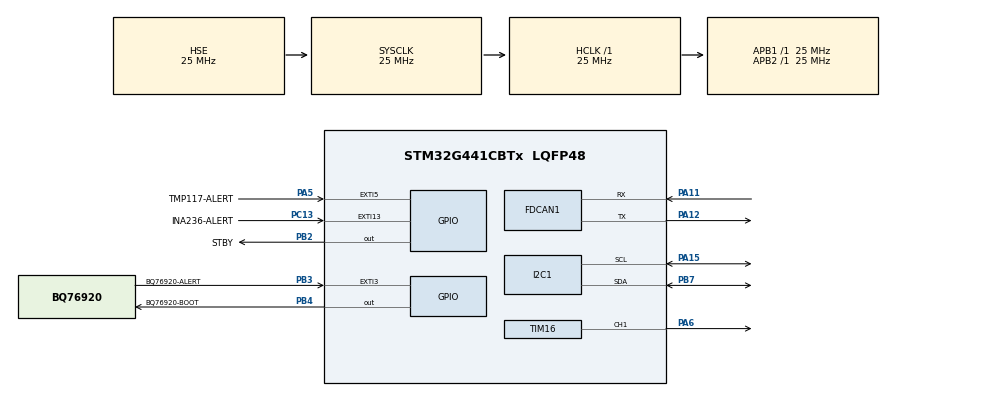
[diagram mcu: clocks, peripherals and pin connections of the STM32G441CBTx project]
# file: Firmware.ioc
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FDCAN1.CalculateBaudRateNominal=520833
FDCAN1.CalculateTimeBitNominal=1920
FDCAN1.CalculateTimeQuantumNominal=640.0
FREERTOS.Tasks01=defaultTask,24,128,StartDefaultTask,Default,NULL,Dynamic,NULL,NULL
I2C1.Timing=0x0080608D
Mcu.Family=STM32G4
Mcu.Name=STM32G441CBTx
Mcu.Package=LQFP48
NVIC.EXTI15_10_IRQn=true\:5\:0\:false\:true\:true\:5\:true\:true\:true\:true
NVIC.EXTI3_IRQn=true\:5\:0\:false\:true\:true\:2\:true\:true\:true\:true
NVIC.EXTI9_5_IRQn=true\:5\:0\:false\:true\:true\:4\:true\:true\:true\:true
NVIC.FDCAN1_IT0_IRQn=true\:5\:0\:false\:true\:true\:3\:true\:true\:true\:true
NVIC.PriorityGroup=NVIC_PRIORITYGROUP_4
NVIC.RCC_IRQn=true\:5\:0\:false\:true\:true\:1\:true\:true\:false\:true
NVIC.TimeBase=TIM6_DAC_IRQn
NVIC.TimeBaseIP=TIM6
PA11.Mode=FDCAN_Activate
PA11.Signal=FDCAN1_RX
PA12.Mode=FDCAN_Activate
PA12.Signal=FDCAN1_TX
PA13.Mode=Serial_Wire
PA13.Signal=SYS_JTMS-SWDIO
PA14.Mode=Serial_Wire
PA14.Signal=SYS_JTCK-SWCLK
PA15.Mode=I2C
PA15.Signal=I2C1_SCL
PA5.GPIO_Label=TMP117-ALERT
PA5.Signal=GPXTI5
PA6.Signal=S_TIM16_CH1
PB2.GPIO_Label=STBY
PB2.Signal=GPIO_Output
PB3.GPIO_Label=BQ76920-ALERT
PB3.Signal=GPXTI3
PB4.GPIO_Label=BQ76920-BOOT
PB4.Signal=GPIO_Output
PB7.Mode=I2C
PB7.Signal=I2C1_SDA
PC13.GPIO_Label=INA236-ALERT
PC13.Signal=GPXTI13
PF0-OSC_IN.Mode=HSE-External-Oscillator
PF0-OSC_IN.Signal=RCC_OSC_IN
PF1-OSC_OUT.Mode=HSE-External-Oscillator
PF1-OSC_OUT.Signal=RCC_OSC_OUT
ProjectManager.HeapSize=0x200
ProjectManager.StackSize=0x400
ProjectManager.TargetToolchain=CMake
RCC.ADC12Freq_Value=25000000
RCC.AHBFreq_Value=25000000
RCC.APB1Freq_Value=25000000
RCC.APB1TimFreq_Value=25000000
RCC.APB2Freq_Value=25000000
RCC.APB2TimFreq_Value=25000000
RCC.CortexFreq_Value=25000000
RCC.EXTERNAL_CLOCK_VALUE=12288000
RCC.HCLKFreq_Value=25000000
RCC.HSE_VALUE=25000000
RCC.HSI48_VALUE=48000000
RCC.HSI_VALUE=16000000
RCC.I2C1CLockSelection=RCC_I2C1CLKSOURCE_SYSCLK
RCC.LSE_VALUE=32768
RCC.PLLSourceVirtual=RCC_PLLSOURCE_HSE
RCC.SYSCLKFreq_VALUE=25000000
RCC.SYSCLKSource=RCC_SYSCLKSOURCE_HSE
RCC.USBFreq_Value=100000000
RCC.VCOOutputFreq_Value=200000000
SH.S_TIM16_CH1.0=TIM16_CH1,PWM Generation1 CH1
TIM16.Channel=TIM_CHANNEL_1
VP_FREERTOS_VS_CMSIS_V2.Mode=CMSIS_V2
VP_SYS_VS_DBSignals.Mode=DisableDeadBatterySignals
VP_SYS_VS_tim6.Mode=TIM6
VP_TIM16_VS_ClockSourceINT.Mode=Enable_Timer
board=custom

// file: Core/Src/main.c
/* USER CODE BEGIN Header */
/**
 ******************************************************************************
 * @file           : main.c
 * @brief          : Main program body
 ******************************************************************************
 * @attention
 *
 * Copyright (c) 2026 STMicroelectronics.
 * All rights reserved.
 *
 * This software is licensed under terms that can be found in the LICENSE file
 * in the root directory of this software component.
 * If no LICENSE file comes with this software, it is provided AS-IS.
 *
 ******************************************************************************
 */
/* USER CODE END Header */
#include "main.h"
#include "INA236.h"
#include "bq76920.h"
#include "tmp117.h"
#include "cmsis_os.h"
#include "cmsis_os2.h"
#include "fdcan.h"
#include "gpio.h"
#include "i2c.h"
#include "ina236.h"
#include "stm32g4xx_hal.h"
#include "tim.h"
#include "tmp117.h"

BQ76920 bq;
INA236 ina;
TMP117 tmp;

void SystemClock_Config(void);
void MX_FREERTOS_Init(void);
static void MX_NVIC_Init(void);

/* USER CODE BEGIN 0 */
void BQ76920Task(void *argument);
void INA236Task(void *argument);
void TMP117Task(void *argument);
/* USER CODE END 0 */

// RTOS Tasks
osThreadId_t BQ76920TaskHandle;
const osThreadAttr_t BQ76920Task_attr = {
    .name = "BQ76920 Task",
    .stack_size = 256 * 4,
    .priority = (osPriority_t)osPriorityNormal,
};

osThreadId_t INA236TaskHandle;
const osThreadAttr_t INA236Task_attr = {
    .name = "INA236 Task",
    .stack_size = 256 * 4,
    .priority = (osPriority_t)osPriorityNormal,
};

osThreadId_t TMP117TaskHandle;
const osThreadAttr_t TMP117Task_attr = {
    .name = "TMP117 Task",
    .stack_size = 256 * 4,
    .priority = (osPriority_t)osPriorityNormal,
};

// Mutexes
osMutexId_t i2cMutex;
const osMutexAttr_t i2cMutex_attr = {.name = "i2cMutex"};
int main(void) {
  SCB->VTOR = 0x08000000;
  __DSB();
  __ISB();

  /* MCU Configuration--------------------------------------------------------*/

  /* Reset of all peripherals, Initializes the Flash interface and the Systick.
   */
  HAL_Init();

  /* Configure the system clock */
  SystemClock_Config();
  /* USER CODE BEGIN SysInit */
  MX_NVIC_Init();
  /* USER CODE END SysInit */
  NVIC_ClearPendingIRQ(TIM6_DAC_IRQn);
  NVIC_SetPendingIRQ(TIM6_DAC_IRQn);

  extern TIM_HandleTypeDef htim6;

  __enable_irq();

  HAL_NVIC_SetPriority(TIM6_DAC_IRQn, 15, 0);
  HAL_NVIC_EnableIRQ(TIM6_DAC_IRQn);

  __HAL_TIM_CLEAR_FLAG(&htim6, TIM_FLAG_UPDATE);
  __HAL_TIM_ENABLE_IT(&htim6, TIM_IT_UPDATE);
  HAL_TIM_Base_Start_IT(&htim6);
  /* Initialize all configured peripherals */
  MX_GPIO_Init();
  MX_FDCAN1_Init();
  MX_I2C1_Init();
  MX_TIM16_Init();

  /* Initialize interrupts */
  MX_NVIC_Init();
  /* USER CODE BEGIN 2 */
  BQ76920_Initialize(&bq, &hi2c1, BQ76920_ALERT_GPIO_Port, BQ76920_ALERT_Pin,
                     BQ76920_BOOT_GPIO_Port, BQ76920_BOOT_Pin);
  readCells(&bq);

  INA236_Initialize(&ina, &hi2c1);
  getINA236(&ina);

  TMP117_Initialize(&tmp, &hi2c1);
  readTMP117(&tmp);
  /* USER CODE END 2 */

  /* Init scheduler */
  osKernelInitialize(); /* Call init function for freertos objects (in
                           cmsis_os2.c) */

  i2cMutex = osMutexNew(&i2cMutex_attr);
  if (i2cMutex == NULL) {
    Error_Handler();
  }
  INA236TaskHandle = osThreadNew(INA236Task, NULL, &INA236Task_attr);
  BQ76920TaskHandle = osThreadNew(BQ76920Task, NULL, &BQ76920Task_attr);
  TMP117TaskHandle = osThreadNew(TMP117Task, NULL, &TMP117Task_attr);
  /* Start scheduler */
  osKernelStart();

  /* We should never get here as control is now taken by the scheduler */

  /* Infinite loop */
  while (1) {

  }
}
void BQ76920Task(void *argument) {
  for (;;) {
    osMutexAcquire(i2cMutex, osWaitForever);
    readCells(&bq);
    osMutexRelease(i2cMutex);
    osDelay(5);
  }
}

void INA236Task(void *argument) {
  for (;;) {
    osMutexAcquire(i2cMutex, osWaitForever);
    getINA236(&ina);
    osMutexRelease(i2cMutex);
    osDelay(5);
  }
}
void TMP117Task(void *argument)
{
  for (;;) {
    osMutexAcquire(i2cMutex, osWaitForever);
    readTMP117(&tmp);
    osMutexRelease(i2cMutex);
    osDelay(5);
  }
}
void SystemClock_Config(void)
{
  RCC_OscInitTypeDef RCC_OscInitStruct = {0};
  RCC_ClkInitTypeDef RCC_ClkInitStruct = {0};

  /** Configure the main internal regulator output voltage
  */
  HAL_PWREx_ControlVoltageScaling(PWR_REGULATOR_VOLTAGE_SCALE1);

  /** Initializes the RCC Oscillators according to the specified parameters
  * in the RCC_OscInitTypeDef structure.
  */
  RCC_OscInitStruct.OscillatorType = RCC_OSCILLATORTYPE_HSE;
  RCC_OscInitStruct.HSEState = RCC_HSE_ON;
  RCC_OscInitStruct.PLL.PLLState = RCC_PLL_NONE;
  if (HAL_RCC_OscConfig(&RCC_OscInitStruct) != HAL_OK)
  {
    Error_Handler();
  }

  /** Initializes the CPU, AHB and APB buses clocks
  */
  RCC_ClkInitStruct.ClockType = RCC_CLOCKTYPE_HCLK|RCC_CLOCKTYPE_SYSCLK
                              |RCC_CLOCKTYPE_PCLK1|RCC_CLOCKTYPE_PCLK2;
  RCC_ClkInitStruct.SYSCLKSource = RCC_SYSCLKSOURCE_HSE;
  RCC_ClkInitStruct.AHBCLKDivider = RCC_SYSCLK_DIV1;
  RCC_ClkInitStruct.APB1CLKDivider = RCC_HCLK_DIV1;
  RCC_ClkInitStruct.APB2CLKDivider = RCC_HCLK_DIV1;

  if (HAL_RCC_ClockConfig(&RCC_ClkInitStruct, FLASH_LATENCY_0) != HAL_OK)
  {
    Error_Handler();
  }
}

/**
  * @brief NVIC Configuration.
  * @retval None
  */
static void MX_NVIC_Init(void)
{
  /* RCC_IRQn interrupt configuration */
  HAL_NVIC_SetPriority(RCC_IRQn, 5, 0);
  HAL_NVIC_EnableIRQ(RCC_IRQn);
  /* EXTI3_IRQn interrupt configuration */
  HAL_NVIC_SetPriority(EXTI3_IRQn, 5, 0);
  HAL_NVIC_EnableIRQ(EXTI3_IRQn);
  /* FDCAN1_IT0_IRQn interrupt configuration */
  HAL_NVIC_SetPriority(FDCAN1_IT0_IRQn, 5, 0);
  HAL_NVIC_EnableIRQ(FDCAN1_IT0_IRQn);
  /* EXTI9_5_IRQn interrupt configuration */
  HAL_NVIC_SetPriority(EXTI9_5_IRQn, 5, 0);
  HAL_NVIC_EnableIRQ(EXTI9_5_IRQn);
  /* EXTI15_10_IRQn interrupt configuration */
  HAL_NVIC_SetPriority(EXTI15_10_IRQn, 5, 0);
  HAL_NVIC_EnableIRQ(EXTI15_10_IRQn);

  HAL_NVIC_SetPriority(TIM6_DAC_IRQn, 15, 0);
  HAL_NVIC_EnableIRQ(TIM6_DAC_IRQn);
}

void HAL_TIM_PeriodElapsedCallback(TIM_HandleTypeDef *htim)
{
  if (htim->Instance == TIM6)
  {
    HAL_IncTick();
  }
}

void Error_Handler(void)
{
  __disable_irq();
  while (1)
  {
  }
}

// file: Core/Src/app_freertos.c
/* USER CODE BEGIN Header */
/**
  ******************************************************************************
  * File Name          : app_freertos.c
  * Description        : Code for freertos applications
  ******************************************************************************
  * @attention
  *
  * Copyright (c) 2026 STMicroelectronics.
  * All rights reserved.
  *
  * This software is licensed under terms that can be found in the LICENSE file
  * in the root directory of this software component.
  * If no LICENSE file comes with this software, it is provided AS-IS.
  *
  ******************************************************************************
  */
/* USER CODE END Header */

#include "FreeRTOS.h"
#include "cmsis_os2.h"
#include "task.h"
#include "main.h"
#include "cmsis_os.h"

/* Definitions for defaultTask */
osThreadId_t defaultTaskHandle;
const osThreadAttr_t defaultTask_attributes = {
  .name = "defaultTask",
  .priority = (osPriority_t) osPriorityLow,
  .stack_size = 128 * 4
};

void StartDefaultTask(void *argument);

void MX_FREERTOS_Init(void); /* (MISRA C 2004 rule 8.1) */

void MX_FREERTOS_Init(void) {

  /* Create the thread(s) */
  /* creation of defaultTask */
  defaultTaskHandle = osThreadNew(StartDefaultTask, NULL, &defaultTask_attributes);

}

void StartDefaultTask(void *argument)
{
  for(;;)
  {
    osDelay(1);
  }
}
